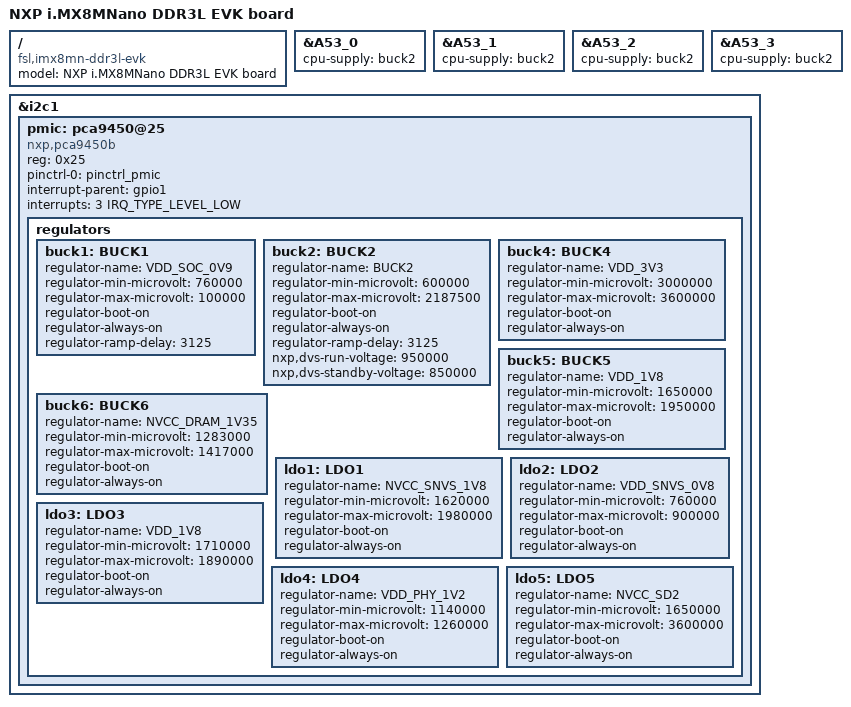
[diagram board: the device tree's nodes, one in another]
// SPDX-License-Identifier: (GPL-2.0+ OR MIT)
/*
 * Copyright 2019 NXP
 */

/dts-v1/;

#include "imx8mn-evk.dtsi"
#include <dt-bindings/interrupt-controller/irq.h>

/ {
	model = "NXP i.MX8MNano DDR3L EVK board";
	compatible = "fsl,imx8mn-ddr3l-evk", "fsl,imx8mn";
};

&A53_0 {
	cpu-supply = <&buck2>;
};

&A53_1 {
	cpu-supply = <&buck2>;
};

&A53_2 {
	cpu-supply = <&buck2>;
};

&A53_3 {
	cpu-supply = <&buck2>;
};

&i2c1 {
	pmic: pca9450@25 {
		compatible = "nxp,pca9450b";
		reg = <0x25>;
		pinctrl-names = "default";
		pinctrl-0 = <&pinctrl_pmic>;
		interrupt-parent = <&gpio1>;
		interrupts = <3 IRQ_TYPE_LEVEL_LOW>;

		regulators {
			buck1: BUCK1 {
				regulator-name = "VDD_SOC_0V9";
				regulator-min-microvolt = <760000>;
				regulator-max-microvolt = <100000>;
				regulator-boot-on;
				regulator-always-on;
				regulator-ramp-delay = <3125>;
			};

			buck2: BUCK2 {
				regulator-name = "BUCK2";
				regulator-min-microvolt = <600000>;
				regulator-max-microvolt = <2187500>;
				regulator-boot-on;
				regulator-always-on;
				regulator-ramp-delay = <3125>;
				nxp,dvs-run-voltage = <950000>;
				nxp,dvs-standby-voltage = <850000>;
			};

			buck4: BUCK4 {
				regulator-name = "VDD_3V3";
				regulator-min-microvolt = <3000000>;
				regulator-max-microvolt = <3600000>;
				regulator-boot-on;
				regulator-always-on;
			};

			buck5: BUCK5 {
				regulator-name = "VDD_1V8";
				regulator-min-microvolt = <1650000>;
				regulator-max-microvolt = <1950000>;
				regulator-boot-on;
				regulator-always-on;
			};

			buck6: BUCK6 {
				regulator-name = "NVCC_DRAM_1V35";
				regulator-min-microvolt = <1283000>;
				regulator-max-microvolt = <1417000>;
				regulator-boot-on;
				regulator-always-on;
			};

			ldo1: LDO1 {
				regulator-name = "NVCC_SNVS_1V8";
				regulator-min-microvolt = <1620000>;
				regulator-max-microvolt = <1980000>;
				regulator-boot-on;
				regulator-always-on;
			};

			ldo2: LDO2 {
				regulator-name = "VDD_SNVS_0V8";
				regulator-min-microvolt = <760000>;
				regulator-max-microvolt = <900000>;
				regulator-boot-on;
				regulator-always-on;
			};

			ldo3: LDO3 {
				regulator-name = "VDD_1V8";
				regulator-min-microvolt = <1710000>;
				regulator-max-microvolt = <1890000>;
				regulator-boot-on;
				regulator-always-on;
			};

			ldo4: LDO4 {
				regulator-name = "VDD_PHY_1V2";
				regulator-min-microvolt = <1140000>;
				regulator-max-microvolt = <1260000>;
				regulator-boot-on;
				regulator-always-on;
			};

			ldo5: LDO5 {
				regulator-name = "NVCC_SD2";
				regulator-min-microvolt = <1650000>;
				regulator-max-microvolt = <3600000>;
				regulator-boot-on;
				regulator-always-on;
			};
		};
	};
};
